# GAP8 register map
Vendor: GreenWaves Technologies SAS; Series: GAP8; File version: 1.3.1
CPU: other r1p0, little endian, MPU, no FPU, I-cache, DTCM, false interrupt priority bits
Registers are 32-bit, read-write, reset 0x0 unless marked. A register's access mark holds for its fields unless they carry their own. Offsets are from the block's base; [hi:lo] are bit positions; {n}, {i} and the like mark numbered series; 'fields as' and 'values as' point back to an identical list.

## apb_adv_timer — Advanced timer
Base 0x1A105000
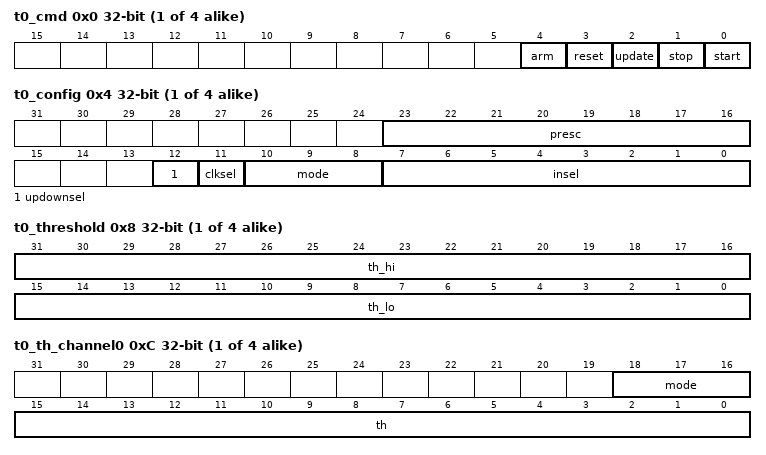
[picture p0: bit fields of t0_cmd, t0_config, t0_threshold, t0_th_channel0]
{0x0+0x40*i} t{i}_cmd (i=0..3) — ADV_TIMER{i} command register.
  [4] arm — ADV_TIMER{i} arm command bitfield.
  [3] reset — ADV_TIMER{i} reset command bitfield.
  [2] update — ADV_TIMER{i} update command bitfield.
  [1] stop — ADV_TIMER{i} stop command bitfield.
  [0] start — ADV_TIMER{i} start command bitfield.
{0x4+0x40*i} t{i}_config (i=0..3) — ADV_TIMER{i} configuration register.
  [23:16] presc — ADV_TIMER{i} prescaler value configuration bitfield.
  [12] updownsel — ADV_TIMER{i} center-aligned mode configuration bitfield
    0=The counter counts up and down alternatively; 1=The counter counts up and resets to 0 when reach threshold
  [11] clksel — ADV_TIMER{i} clock source configuration bitfield
    0=fll (set to FLL); 1=reference clock at 32kHz
  [10:8] mode — ADV_TIMER{i} trigger mode configuration bitfield
    0=trigger event at each clock cycle; 1=trigger event if input source is 0; 2=trigger event if input source is 1; 3=trigger event on input source rising edge; 4=trigger event on input source falling edge; 5=trigger event on input source falling or rising edge; 6=trigger event on input source rising edge when armed; 7=trigger event on input source falling edge when armed
  [7:0] insel — ADV_TIMER{i} input source configuration bitfield: - 0-31: GPIO[0] to GPIO[31] - 32-35: Channel 0 to 3 of ADV_TIMER0 - 36-39: Channel 0 to 3 of ADV_TIMER1 - 40-43: Channel 0 to 3 of ADV_TIMER2 - 44-47: Channel 0 to 3 of ADV_TIMER3
{0x8+0x40*i} t{i}_threshold (i=0..3) — ADV_TIMER{i} threshold configuration register.
  [31:16] th_hi — ADV_TIMER{i} threshold high part configuration bitfield. It defines end counter value.
  [15:0] th_lo — ADV_TIMER{i} threshold low part configuration bitfield. It defines start counter value.
{0xC+0x40*i} t{i}_th_channel0 (i=0..3) — ADV_TIMER{i} channel 0 threshold configuration register.
  [18:16] mode — ADV_TIMER{i} channel 0 threshold match action on channel output signal configuration bitfield
    0=set (set to set.); 1=toggle then next threshold match action is clear; 2=set then next threshold match action is clear; 3=toggle (set to toggle.); 4=clear (set to clear.); 5=toggle then next threshold match action is set; 6=clear then next threshold match action is set
  [15:0] th — ADV_TIMER{i} channel 0 threshold configuration bitfield.
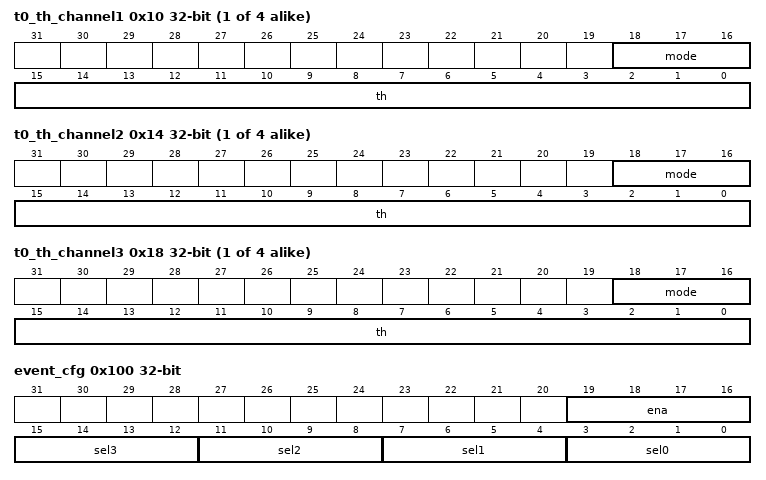
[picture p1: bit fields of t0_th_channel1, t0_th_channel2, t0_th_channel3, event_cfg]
{0x10+0x40*i} t{i}_th_channel1 (i=0..3) — ADV_TIMER{i} channel 1 threshold configuration register.
  [18:16] mode — ADV_TIMER{i} channel 1 threshold match action on channel output signal configuration bitfield
    values as t0_th_channel0.mode
  [15:0] th — ADV_TIMER{i} channel 1 threshold configuration bitfield.
{0x14+0x40*i} t{i}_th_channel2 (i=0..3) — ADV_TIMER{i} channel 2 threshold configuration register.
  [18:16] mode — ADV_TIMER{i} channel 2 threshold match action on channel output signal configuration bitfield
    values as t0_th_channel0.mode
  [15:0] th — ADV_TIMER{i} channel 2 threshold configuration bitfield.
{0x18+0x40*i} t{i}_th_channel3 (i=0..3) — ADV_TIMER{i} channel 3 threshold configuration register.
  [18:16] mode — ADV_TIMER{i} channel 3 threshold match action on channel output signal configuration bitfield
    values as t0_th_channel0.mode
  [15:0] th — ADV_TIMER{i} channel 3 threshold configuration bitfield.
{0x2C+0x40*i} t{i}_counter ro (i=0..3) — ADV_TIMER{i} counter register.
0x100 event_cfg — ADV_TIMERS events configuration register.
  [19:16] ena — ADV_TIMER output event enable configuration bitfield. ENA[i]=1 enables output event i generation.
  [4n+3:4n] sel{n} (n=0..3) — ADV_TIMER output event {n} source configuration bitfiled
    {v}=ADV_TIMER0 channel {v} (v=0..3); {v}=ADV_TIMER1 channel {v-4} (v=4..7); {v}=ADV_TIMER2 channel {v-8} (v=8..11); {v}=ADV_TIMER3 channel {v-12} (v=12..15)
0x104 cg — ADV_TIMERS channels clock gating configuration register.
  [15:0] ena — ADV_TIMER clock gating configuration bitfield. - ENA[i]=0: clock gate ADV_TIMERi. - ENA[i]=1: enable ADV_TIMERi.
